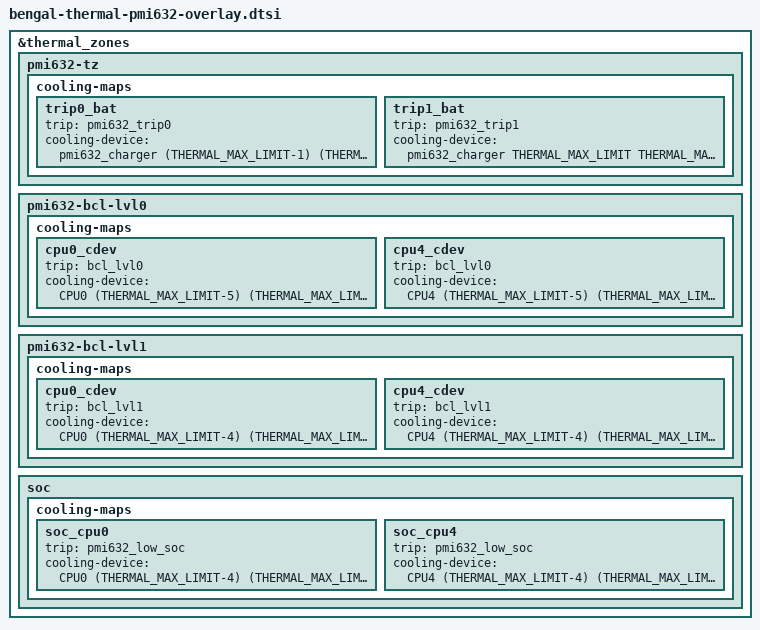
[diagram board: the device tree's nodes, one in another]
#include <dt-bindings/thermal/thermal.h>

&thermal_zones {
	pmi632-tz {
		cooling-maps {
			trip0_bat {
				trip = <&pmi632_trip0>;
				cooling-device =
					<&pmi632_charger (THERMAL_MAX_LIMIT-1)
						(THERMAL_MAX_LIMIT-1)>;
			};

			trip1_bat {
				trip = <&pmi632_trip1>;
				cooling-device =
					<&pmi632_charger THERMAL_MAX_LIMIT
						THERMAL_MAX_LIMIT>;
			};
		};
	};

	pmi632-bcl-lvl0 {
		cooling-maps {
			cpu0_cdev {
				trip = <&bcl_lvl0>;
				cooling-device =
					<&CPU0 (THERMAL_MAX_LIMIT-5)
						(THERMAL_MAX_LIMIT-5)>;
			};

			cpu4_cdev {
				trip = <&bcl_lvl0>;
				cooling-device =
					<&CPU4 (THERMAL_MAX_LIMIT-5)
						(THERMAL_MAX_LIMIT-5)>;
			};
		};
	};

	pmi632-bcl-lvl1 {
		cooling-maps {
			cpu0_cdev {
				trip = <&bcl_lvl1>;
				cooling-device =
					<&CPU0 (THERMAL_MAX_LIMIT-4)
						(THERMAL_MAX_LIMIT-4)>;
			};

			cpu4_cdev {
				trip = <&bcl_lvl1>;
				cooling-device =
					<&CPU4 (THERMAL_MAX_LIMIT-4)
						(THERMAL_MAX_LIMIT-4)>;
			};
		};
	};

	soc {
		cooling-maps {
			soc_cpu0 {
				trip = <&pmi632_low_soc>;
				cooling-device =
					<&CPU0 (THERMAL_MAX_LIMIT-4)
						(THERMAL_MAX_LIMIT-4)>;
			};

			soc_cpu4 {
				trip = <&pmi632_low_soc>;
				cooling-device =
					<&CPU4 (THERMAL_MAX_LIMIT-4)
						(THERMAL_MAX_LIMIT-4)>;
			};

		};
	};
};
